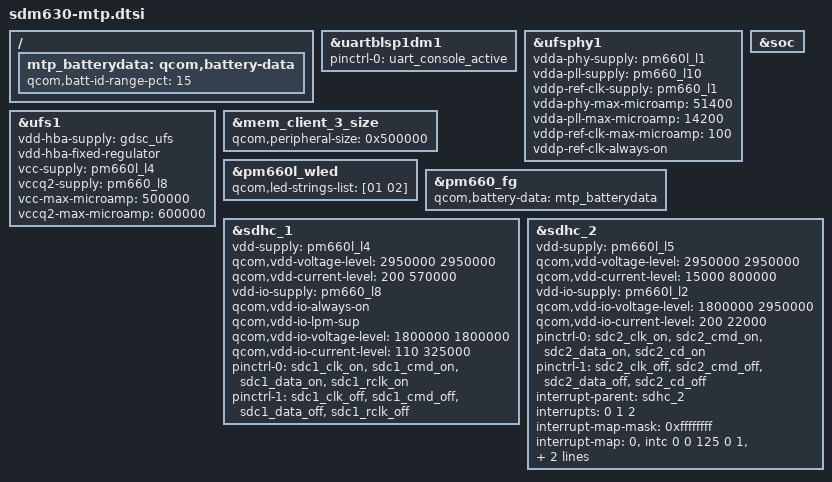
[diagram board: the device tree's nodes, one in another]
/* Copyright (c) 2017, The Linux Foundation. All rights reserved.
 *
 * This program is free software; you can redistribute it and/or modify
 * it under the terms of the GNU General Public License version 2 and
 * only version 2 as published by the Free Software Foundation.
 *
 * This program is distributed in the hope that it will be useful,
 * but WITHOUT ANY WARRANTY; without even the implied warranty of
 * MERCHANTABILITY or FITNESS FOR A PARTICULAR PURPOSE.  See the
 * GNU General Public License for more details.
 */

#include "sdm660-pinctrl.dtsi"
#include "sdm660-camera-sensor-mtp.dtsi"
/ {
	mtp_batterydata: qcom,battery-data {
		qcom,batt-id-range-pct = <15>;
		#include "fg-gen3-batterydata-itech-3000mah.dtsi"
		#include "fg-gen3-batterydata-ascent-3450mah.dtsi"
	};
};

&uartblsp1dm1 {
	status = "ok";
	pinctrl-names = "default";
	pinctrl-0 = <&uart_console_active>;
};

&ufsphy1 {
	vdda-phy-supply = <&pm660l_l1>;
	vdda-pll-supply = <&pm660_l10>;
	vddp-ref-clk-supply = <&pm660_l1>;
	vdda-phy-max-microamp = <51400>;
	vdda-pll-max-microamp = <14200>;
	vddp-ref-clk-max-microamp = <100>;
	vddp-ref-clk-always-on;
	status = "ok";
};

&ufs1 {
	vdd-hba-supply = <&gdsc_ufs>;
	vdd-hba-fixed-regulator;
	vcc-supply = <&pm660l_l4>;
	vccq2-supply = <&pm660_l8>;
	vcc-max-microamp = <500000>;
	vccq2-max-microamp = <600000>;
	status = "ok";
};

&mem_client_3_size {
	qcom,peripheral-size = <0x500000>;
};

&pm660l_wled {
	qcom,led-strings-list = [01 02];
};

&soc {
};

&pm660_fg {
	qcom,battery-data = <&mtp_batterydata>;
};

&sdhc_1 {
	/* device core power supply */
	vdd-supply = <&pm660l_l4>;
	qcom,vdd-voltage-level = <2950000 2950000>;
	qcom,vdd-current-level = <200 570000>;

	/* device communication power supply */
	vdd-io-supply = <&pm660_l8>;
	qcom,vdd-io-always-on;
	qcom,vdd-io-lpm-sup;
	qcom,vdd-io-voltage-level = <1800000 1800000>;
	qcom,vdd-io-current-level = <110 325000>;

	pinctrl-names = "active", "sleep";
	pinctrl-0 = <&sdc1_clk_on &sdc1_cmd_on &sdc1_data_on &sdc1_rclk_on>;
	pinctrl-1 = <&sdc1_clk_off &sdc1_cmd_off &sdc1_data_off &sdc1_rclk_off>;

	status = "ok";
};

&sdhc_2 {
	/* device core power supply */
	vdd-supply = <&pm660l_l5>;
	qcom,vdd-voltage-level = <2950000 2950000>;
	qcom,vdd-current-level = <15000 800000>;

	/* device communication power supply */
	vdd-io-supply = <&pm660l_l2>;
	qcom,vdd-io-voltage-level = <1800000 2950000>;
	qcom,vdd-io-current-level = <200 22000>;

	pinctrl-names = "active", "sleep";
	pinctrl-0 = <&sdc2_clk_on &sdc2_cmd_on &sdc2_data_on &sdc2_cd_on>;
	pinctrl-1 = <&sdc2_clk_off &sdc2_cmd_off &sdc2_data_off &sdc2_cd_off>;

	#address-cells = <0>;
	interrupt-parent = <&sdhc_2>;
	interrupts = <0 1 2>;
	#interrupt-cells = <1>;
	interrupt-map-mask = <0xffffffff>;
	interrupt-map = <0 &intc 0 0 125 0
			1 &intc 0 0 221 0
			2 &tlmm 54 0>;
	interrupt-names = "hc_irq", "pwr_irq", "status_irq";
	cd-gpios = <&tlmm 54 0x1>;

	status = "ok";
};
